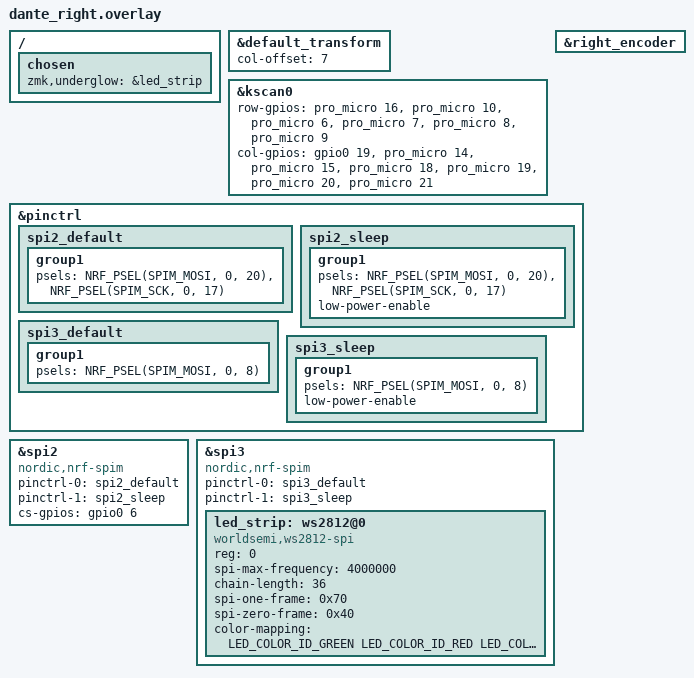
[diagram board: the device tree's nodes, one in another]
/*
 * Copyright (c) 2020 Ryan Cross
 *
 * SPDX-License-Identifier: MIT
 */

#include "dante.dtsi"

&default_transform {
    col-offset = <7>;
};

&kscan0 {
		row-gpios
				= <&pro_micro 16 (GPIO_ACTIVE_HIGH | GPIO_PULL_DOWN)>
				, <&pro_micro 10 (GPIO_ACTIVE_HIGH | GPIO_PULL_DOWN)>
				, <&pro_micro 6 (GPIO_ACTIVE_HIGH | GPIO_PULL_DOWN)>
				, <&pro_micro 7 (GPIO_ACTIVE_HIGH | GPIO_PULL_DOWN)>
				, <&pro_micro 8 (GPIO_ACTIVE_HIGH | GPIO_PULL_DOWN)>
				, <&pro_micro 9 (GPIO_ACTIVE_HIGH | GPIO_PULL_DOWN)>
				;
    col-gpios
        = <&gpio0 19 GPIO_ACTIVE_HIGH>
        , <&pro_micro 14 GPIO_ACTIVE_HIGH>
        , <&pro_micro 15 GPIO_ACTIVE_HIGH>
        , <&pro_micro 18 GPIO_ACTIVE_HIGH>
        , <&pro_micro 19 GPIO_ACTIVE_HIGH>
        , <&pro_micro 20 GPIO_ACTIVE_HIGH>
        , <&pro_micro 21 GPIO_ACTIVE_HIGH>
        ;
};

&right_encoder {
    status = "okay";
};


#include <dt-bindings/led/led.h>

&pinctrl {
    spi2_default: spi2_default {
        group1 {
            psels = <NRF_PSEL(SPIM_MOSI, 0, 20)>,
            <NRF_PSEL(SPIM_SCK, 0, 17)>;
        };
    };

    spi2_sleep: spi2_sleep {
        group1 {
            psels = <NRF_PSEL(SPIM_MOSI, 0, 20)>,
            <NRF_PSEL(SPIM_SCK, 0, 17)>;
            low-power-enable;
        };
    };
};


lpm_view_spi: &spi2 {
    compatible = "nordic,nrf-spim";
    pinctrl-0 = <&spi2_default>;
    pinctrl-1 = <&spi2_sleep>;
    pinctrl-names = "default", "sleep";
    cs-gpios = <&gpio0 6 GPIO_ACTIVE_HIGH>;
};

nice_view_spi: &spi2 {
    compatible = "nordic,nrf-spim";
    pinctrl-0 = <&spi2_default>;
    pinctrl-1 = <&spi2_sleep>;
    pinctrl-names = "default", "sleep";
    cs-gpios = <&gpio0 6 GPIO_ACTIVE_HIGH>;
};

&pinctrl {
    spi3_default: spi3_default {
        group1 {
            psels = <NRF_PSEL(SPIM_MOSI, 0, 8)>;
        };
    };

    spi3_sleep: spi3_sleep {
        group1 {
            psels = <NRF_PSEL(SPIM_MOSI, 0, 8)>;
            low-power-enable;
        };
    };
};

&spi3 {
    compatible = "nordic,nrf-spim";
    status = "okay";

    pinctrl-0 = <&spi3_default>;
    pinctrl-1 = <&spi3_sleep>;
    pinctrl-names = "default", "sleep";

    led_strip: ws2812@0 {
        compatible = "worldsemi,ws2812-spi";

        /* SPI */
        reg = <0>; /* ignored, but necessary for SPI bindings */
        spi-max-frequency = <4000000>;

        /* WS2812 */
        chain-length = <36>; /* arbitrary; change at will */
        spi-one-frame = <0x70>;
        spi-zero-frame = <0x40>;

        color-mapping = <
            LED_COLOR_ID_GREEN
            LED_COLOR_ID_RED
            LED_COLOR_ID_BLUE
        >;
    };
};

/ {
    chosen {
        zmk,underglow = &led_strip;
    };
};
